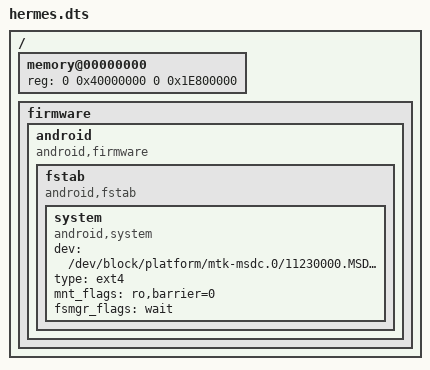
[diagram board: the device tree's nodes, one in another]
/*
 * Mediatek's MT6795 SoC device tree source
 *
 * Copyright (c) 2013 MediaTek Co., Ltd.
 *              http://www.mediatek.com
 *
 */

/dts-v1/;

/include/ "mt6795.dtsi"
/include/ "cust_eint.dtsi"
/ {
	memory@00000000 {
		device_type = "memory";
		reg = <0 0x40000000 0 0x1E800000>;
	};
/* Early Mount Partitions Start */
	firmware {
		android {
			compatible = "android,firmware";
			fstab {
				compatible = "android,fstab";
				system {
					compatible = "android,system";
					dev = "/dev/block/platform/mtk-msdc.0/11230000.MSDC0/by-name/system";
					type = "ext4";
					mnt_flags = "ro,barrier=0";
					fsmgr_flags = "wait";
					status = "ok";
				};
			};
		};
	};
/* Early Mount Partitions End */
};
